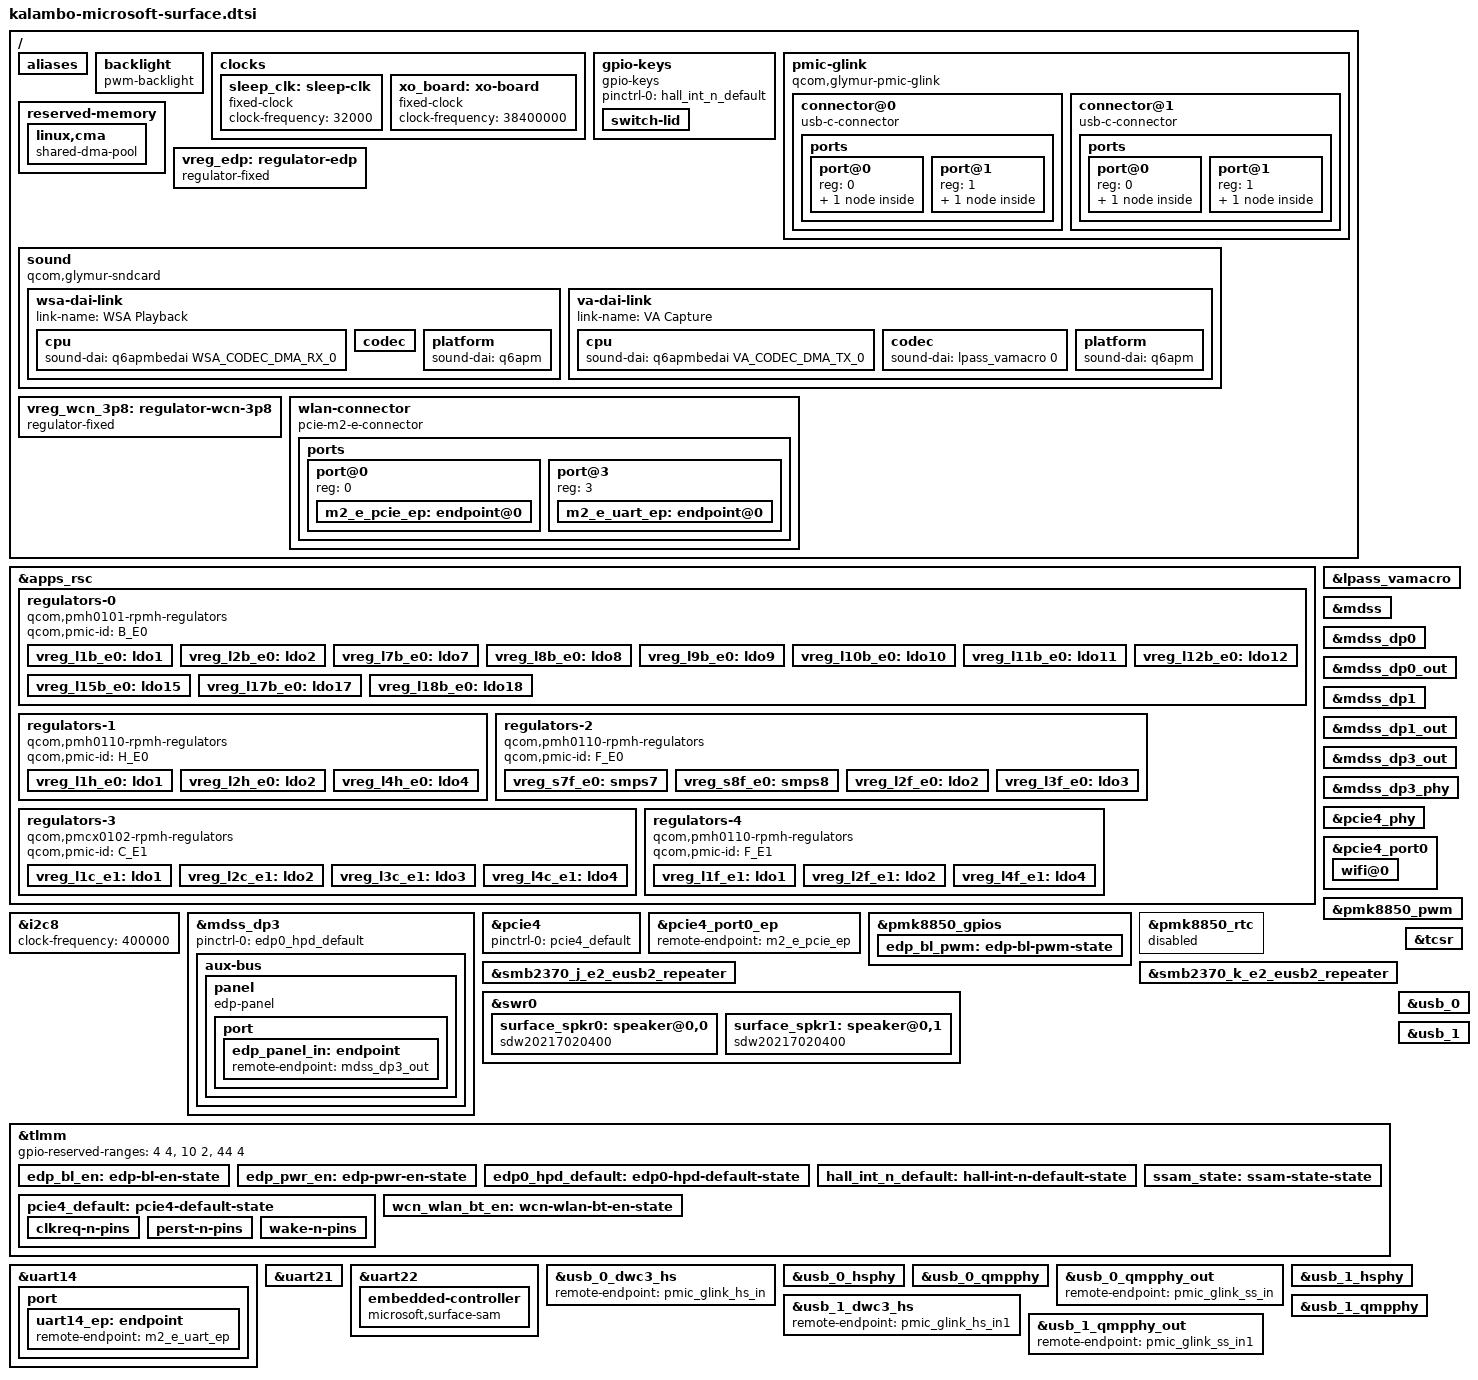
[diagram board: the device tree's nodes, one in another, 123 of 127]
// SPDX-License-Identifier: BSD-3-Clause
/*
 * Parts shared by the Microsoft Surface devices with the 6-core Snapdragon
 * X2 Plus X2P-42-100 (Kalambo): Surface Laptop 13-inch (2nd Edition) and
 * Surface Pro 12-inch (2nd Edition).
 *
 * The PEP power tables of both devices' ACPI tables are the Surface Laptop
 * 8's (Mahua) rail for rail, and their SoC side devices (Surface Serial Hub
 * on UR23, Bluetooth on UR15, Wi-Fi on PCI4, the eDP pins, the speaker
 * amplifier pins) sit where the Surface Laptop 8's do. The SoC wiring is
 * therefore the one glymur-microsoft-surface-laptop8.dts describes, without
 * its USB4 routers: both devices' ACPI tables disable the USB4 router
 * device (UBF0).
 *
 * Copyright (c) Qualcomm Technologies, Inc. and/or its subsidiaries.
 */

#include "pmcx0102.dtsi"
#include "pmh0101.dtsi"
#include "pmh0110-glymur.dtsi"
#include "pmk8850.dtsi"
#include "smb2370.dtsi"

#include <dt-bindings/input/gpio-keys.h>
#include <dt-bindings/input/input.h>

/* As mahua-crd.dts: one pmcx0102 die on SPMI0. */
/delete-node/ &pmcx0102_d_e0;
/delete-node/ &pmcx0102_d0_thermal;

/ {
	aliases {
		i2c8 = &i2c8;

		serial0 = &uart21;
		serial1 = &uart14;
	};

	backlight: backlight {
		compatible = "pwm-backlight";
		pwms = <&pmk8850_pwm 0 5118750>;

		pinctrl-0 = <&edp_bl_pwm>;
		pinctrl-names = "default";
	};

	clocks {
		sleep_clk: sleep-clk {
			compatible = "fixed-clock";
			clock-frequency = <32000>;
			#clock-cells = <0>;
		};

		xo_board: xo-board {
			compatible = "fixed-clock";
			clock-frequency = <38400000>;
			#clock-cells = <0>;
		};
	};

	/*
	 * ACPI \_SB.GIO0.LIDR reads TLMM 2 and \_SB.LIGE takes its wake
	 * interrupt from it on both edges. On the tablet it is the type
	 * cover's Hall sensor.
	 */
	gpio-keys {
		compatible = "gpio-keys";

		pinctrl-0 = <&hall_int_n_default>;
		pinctrl-names = "default";

		switch-lid {
			label = "lid";
			gpios = <&tlmm 2 GPIO_ACTIVE_LOW>;
			linux,input-type = <EV_SW>;
			linux,code = <SW_LID>;
			wakeup-source;
		};
	};

	pmic-glink {
		compatible = "qcom,glymur-pmic-glink",
			     "qcom,pmic-glink";
		#address-cells = <1>;
		#size-cells = <0>;

		connector@0 {
			compatible = "usb-c-connector";
			reg = <0>;
			power-role = "dual";
			data-role = "dual";

			ports {
				#address-cells = <1>;
				#size-cells = <0>;

				port@0 {
					reg = <0>;

					pmic_glink_hs_in: endpoint {
						remote-endpoint = <&usb_0_dwc3_hs>;
					};
				};

				port@1 {
					reg = <1>;

					pmic_glink_ss_in: endpoint {
						remote-endpoint = <&usb_0_qmpphy_out>;
					};
				};
			};
		};

		connector@1 {
			compatible = "usb-c-connector";
			reg = <1>;
			power-role = "dual";
			data-role = "dual";

			ports {
				#address-cells = <1>;
				#size-cells = <0>;

				port@0 {
					reg = <0>;

					pmic_glink_hs_in1: endpoint {
						remote-endpoint = <&usb_1_dwc3_hs>;
					};
				};

				port@1 {
					reg = <1>;

					pmic_glink_ss_in1: endpoint {
						remote-endpoint = <&usb_1_qmpphy_out>;
					};
				};
			};
		};
	};

	reserved-memory {
		linux,cma {
			compatible = "shared-dma-pool";
			size = <0x0 0x10000000>;
			reusable;
			linux,cma-default;
		};
	};

	/* ACPI GPU0 power table: TLMM 70 on for the panel */
	vreg_edp: regulator-edp {
		compatible = "regulator-fixed";

		regulator-name = "VREG_EDP_3P3";
		regulator-min-microvolt = <3300000>;
		regulator-max-microvolt = <3300000>;

		gpio = <&tlmm 70 GPIO_ACTIVE_HIGH>;
		enable-active-high;

		vin-supply = <&vreg_l8b_e0>;

		pinctrl-0 = <&edp_pwr_en>;
		pinctrl-names = "default";

		regulator-boot-on;
	};

	/*
	 * The two WSA8845 amplifiers and two DMICs of the Surface Laptop 8,
	 * whose topology this names: the ACPI audio pins (AUCD, TLMM 204 and
	 * 205) are the Surface Laptop 8's.
	 */
	sound {
		compatible = "qcom,glymur-sndcard";
		model = "GLYMUR-Microsoft-Surface-Laptop-8";
		audio-routing = "SpkrLeft IN", "WSA WSA_SPK1 OUT",
				"SpkrRight IN", "WSA WSA_SPK2 OUT",
				"VA DMIC0", "vdd-micb",
				"VA DMIC1", "vdd-micb";

		wsa-dai-link {
			link-name = "WSA Playback";

			cpu {
				sound-dai = <&q6apmbedai WSA_CODEC_DMA_RX_0>;
			};

			codec {
				sound-dai = <&surface_spkr0>, <&surface_spkr1>,
					    <&swr0 0>, <&lpass_wsamacro 0>;
			};

			platform {
				sound-dai = <&q6apm>;
			};
		};

		va-dai-link {
			link-name = "VA Capture";

			cpu {
				sound-dai = <&q6apmbedai VA_CODEC_DMA_TX_0>;
			};

			codec {
				sound-dai = <&lpass_vamacro 0>;
			};

			platform {
				sound-dai = <&q6apm>;
			};
		};
	};

	/*
	 * ACPI QPPX drives TLMM 117 (Wi-Fi enable) and BTH0 TLMM 116
	 * (Bluetooth enable), the Surface Laptop 8's pins.
	 */
	/*
	 * The Wi-Fi module's main supply. The tables name its INA4230 channel
	 * (WIFI_3P8V) but switch it with no GPIO, so it is always on.
	 */
	vreg_wcn_3p8: regulator-wcn-3p8 {
		compatible = "regulator-fixed";

		regulator-name = "VREG_WCN_3P8";
		regulator-min-microvolt = <3800000>;
		regulator-max-microvolt = <3800000>;

		regulator-always-on;
	};

	wlan-connector {
		compatible = "pcie-m2-e-connector";
		vpcie3v3-supply = <&vreg_wcn_3p8>;
		vpcie1v8-supply = <&vreg_l15b_e0>;

		w-disable1-gpios = <&tlmm 117 GPIO_ACTIVE_LOW>;
		w-disable2-gpios = <&tlmm 116 GPIO_ACTIVE_LOW>;

		pinctrl-0 = <&wcn_wlan_bt_en>;
		pinctrl-names = "default";

		ports {
			#address-cells = <1>;
			#size-cells = <0>;

			port@0 {
				reg = <0>;
				#address-cells = <1>;
				#size-cells = <0>;

				m2_e_pcie_ep: endpoint@0 {
					reg = <0>;
					remote-endpoint = <&pcie4_port0_ep>;
				};
			};

			port@3 {
				reg = <3>;
				#address-cells = <1>;
				#size-cells = <0>;

				m2_e_uart_ep: endpoint@0 {
					reg = <0>;
					remote-endpoint = <&uart14_ep>;
				};
			};
		};
	};
};

/* The PEP rails are the Surface Laptop 8's, and so are these regulators. */
&apps_rsc {
	/* PMH0101 */
	regulators-0 {
		compatible = "qcom,pmh0101-rpmh-regulators";
		qcom,pmic-id = "B_E0";

		vreg_l1b_e0: ldo1 {
			regulator-name = "vreg_l1b_e0";
			regulator-min-microvolt = <1800000>;
			regulator-max-microvolt = <1800000>;
			regulator-initial-mode = <RPMH_REGULATOR_MODE_HPM>;
		};

		/* Unused */
		vreg_l2b_e0: ldo2 {
			regulator-name = "vreg_l2b_e0";
			regulator-min-microvolt = <1800000>;
			regulator-max-microvolt = <1800000>;
		};

		vreg_l7b_e0: ldo7 {
			regulator-name = "vreg_l7b_e0";
			regulator-min-microvolt = <3072000>;
			regulator-max-microvolt = <3072000>;
			regulator-initial-mode = <RPMH_REGULATOR_MODE_HPM>;
		};

		vreg_l8b_e0: ldo8 {
			regulator-name = "vreg_l8b_e0";
			regulator-min-microvolt = <3072000>;
			regulator-max-microvolt = <3304000>;
			regulator-initial-mode = <RPMH_REGULATOR_MODE_HPM>;
		};

		/* Unused */
		vreg_l9b_e0: ldo9 {
			regulator-name = "vreg_l9b_e0";
			regulator-min-microvolt = <2960000>;
			regulator-max-microvolt = <2960000>;
		};

		vreg_l10b_e0: ldo10 {
			regulator-name = "vreg_l10b_e0";
			regulator-min-microvolt = <1800000>;
			regulator-max-microvolt = <1800000>;
			regulator-initial-mode = <RPMH_REGULATOR_MODE_HPM>;
		};

		vreg_l11b_e0: ldo11 {
			regulator-name = "vreg_l11b_e0";
			regulator-min-microvolt = <1200000>;
			regulator-max-microvolt = <1200000>;
			regulator-initial-mode = <RPMH_REGULATOR_MODE_HPM>;
		};

		/* Unused */
		vreg_l12b_e0: ldo12 {
			regulator-name = "vreg_l12b_e0";
			regulator-min-microvolt = <1200000>;
			regulator-max-microvolt = <1200000>;
		};

		vreg_l15b_e0: ldo15 {
			regulator-name = "vreg_l15b_e0";
			regulator-min-microvolt = <1800000>;
			regulator-max-microvolt = <1800000>;
			regulator-initial-mode = <RPMH_REGULATOR_MODE_HPM>;
			/* Provides reference voltage for many undescribed components */
			regulator-always-on;
		};

		/* Unused */
		vreg_l17b_e0: ldo17 {
			regulator-name = "vreg_l17b_e0";
			regulator-min-microvolt = <2504000>;
			regulator-max-microvolt = <2504000>;
		};

		vreg_l18b_e0: ldo18 {
			regulator-name = "vreg_l18b_e0";
			regulator-min-microvolt = <1200000>;
			regulator-max-microvolt = <1200000>;
			regulator-initial-mode = <RPMH_REGULATOR_MODE_HPM>;

			/* Provides reference voltage for many undescribed components */
			regulator-always-on;
		};
	};

	/* PMH0110 H_E0: USB PHY, PCIe 5 PHY and reference rails (firmware power tables) */
	regulators-1 {
		compatible = "qcom,pmh0110-rpmh-regulators";
		qcom,pmic-id = "H_E0";

		vreg_l1h_e0: ldo1 {
			regulator-name = "vreg_l1h_e0";
			regulator-min-microvolt = <936000>;
			regulator-max-microvolt = <936000>;
			regulator-initial-mode = <RPMH_REGULATOR_MODE_HPM>;
		};

		vreg_l2h_e0: ldo2 {
			regulator-name = "vreg_l2h_e0";
			regulator-min-microvolt = <880000>;
			regulator-max-microvolt = <880000>;
			regulator-initial-mode = <RPMH_REGULATOR_MODE_HPM>;
		};

		vreg_l4h_e0: ldo4 {
			regulator-name = "vreg_l4h_e0";
			regulator-min-microvolt = <1200000>;
			regulator-max-microvolt = <1200000>;
			regulator-initial-mode = <RPMH_REGULATOR_MODE_HPM>;
		};
	};

	/* PMH0110 */
	regulators-2 {
		compatible = "qcom,pmh0110-rpmh-regulators";
		qcom,pmic-id = "F_E0";

		vreg_s7f_e0: smps7 {
			regulator-name = "vreg_s7f_e0";
			regulator-min-microvolt = <1200000>;
			regulator-max-microvolt = <1200000>;
			regulator-initial-mode = <RPMH_REGULATOR_MODE_HPM>;
		};

		vreg_s8f_e0: smps8 {
			regulator-name = "vreg_s8f_e0";
			regulator-min-microvolt = <952000>;
			regulator-max-microvolt = <952000>;
			regulator-initial-mode = <RPMH_REGULATOR_MODE_HPM>;
		};

		vreg_l2f_e0: ldo2 {
			regulator-name = "vreg_l2f_e0";
			regulator-min-microvolt = <936000>;
			regulator-max-microvolt = <936000>;
			regulator-initial-mode = <RPMH_REGULATOR_MODE_HPM>;
		};

		vreg_l3f_e0: ldo3 {
			regulator-name = "vreg_l3f_e0";
			regulator-min-microvolt = <912000>;
			regulator-max-microvolt = <912000>;
			regulator-initial-mode = <RPMH_REGULATOR_MODE_HPM>;
		};
	};

	regulators-3 {
		compatible = "qcom,pmcx0102-rpmh-regulators";
		qcom,pmic-id = "C_E1";

		vreg_l1c_e1: ldo1 {
			regulator-name = "vreg_l1c_e1";
			regulator-min-microvolt = <912000>;
			regulator-max-microvolt = <912000>;
			regulator-initial-mode = <RPMH_REGULATOR_MODE_HPM>;
		};

		vreg_l2c_e1: ldo2 {
			regulator-name = "vreg_l2c_e1";
			regulator-min-microvolt = <1200000>;
			regulator-max-microvolt = <1200000>;
			regulator-initial-mode = <RPMH_REGULATOR_MODE_HPM>;
		};

		vreg_l3c_e1: ldo3 {
			regulator-name = "vreg_l3c_e1";
			regulator-min-microvolt = <936000>;
			regulator-max-microvolt = <936000>;
			regulator-initial-mode = <RPMH_REGULATOR_MODE_HPM>;
		};

		vreg_l4c_e1: ldo4 {
			regulator-name = "vreg_l4c_e1";
			regulator-min-microvolt = <912000>;
			regulator-max-microvolt = <912000>;
			regulator-initial-mode = <RPMH_REGULATOR_MODE_HPM>;
		};
	};

	/* PMH0110 */
	regulators-4 {
		compatible = "qcom,pmh0110-rpmh-regulators";
		qcom,pmic-id = "F_E1";

		vreg_l1f_e1: ldo1 {
			regulator-name = "vreg_l1f_e1";
			regulator-min-microvolt = <904000>;
			regulator-max-microvolt = <904000>;
			regulator-initial-mode = <RPMH_REGULATOR_MODE_HPM>;
		};

		vreg_l2f_e1: ldo2 {
			regulator-name = "vreg_l2f_e1";
			regulator-min-microvolt = <880000>;
			regulator-max-microvolt = <880000>;
			regulator-initial-mode = <RPMH_REGULATOR_MODE_HPM>;
		};

		vreg_l4f_e1: ldo4 {
			regulator-name = "vreg_l4f_e1";
			regulator-min-microvolt = <1200000>;
			regulator-max-microvolt = <1200000>;
			regulator-initial-mode = <RPMH_REGULATOR_MODE_HPM>;
		};
	};
};

&i2c8 {
	clock-frequency = <400000>;

	status = "okay";
};

&lpass_vamacro {
	vdd-micb-supply = <&vreg_l1b_e0>;

	pinctrl-0 = <&dmic01_default>;
	pinctrl-names = "default";

	qcom,dmic-sample-rate = <2400000>;
};

&mdss {
	status = "okay";
};

/* DisplayPort alternate mode on the two USB-C ports */
&mdss_dp0 {
	status = "okay";
};

&mdss_dp0_out {
	link-frequencies = /bits/ 64 <1620000000 2700000000 5400000000 8100000000>;
};

&mdss_dp1 {
	status = "okay";
};

&mdss_dp1_out {
	link-frequencies = /bits/ 64 <1620000000 2700000000 5400000000 8100000000>;
};

&mdss_dp3 {
	/delete-property/ #sound-dai-cells;

	pinctrl-0 = <&edp0_hpd_default>;
	pinctrl-names = "default";

	status = "okay";

	aux-bus {
		panel {
			/*
			 * ACPI GPU0 power table: TLMM 70 (power), TLMM 18
			 * (enable) and TLMM 119 (hot plug), and PMK8850 GPIO 5
			 * as the backlight PWM output.
			 */
			compatible = "edp-panel";
			backlight = <&backlight>;
			enable-gpios = <&tlmm 18 GPIO_ACTIVE_HIGH>;
			power-supply = <&vreg_edp>;

			pinctrl-0 = <&edp_bl_en>;
			pinctrl-names = "default";

			port {
				edp_panel_in: endpoint {
					remote-endpoint = <&mdss_dp3_out>;
				};
			};
		};
	};
};

&mdss_dp3_out {
	/* The rates the Surface Laptop 8's eDP link has run at */
	data-lanes = <0 1 2 3>;
	link-frequencies = /bits/ 64 <1620000000 2700000000 5400000000>;

	remote-endpoint = <&edp_panel_in>;
};

&mdss_dp3_phy {
	vdda-phy-supply = <&vreg_l2f_e1>;
	vdda-pll-supply = <&vreg_l4f_e1>;

	status = "okay";
};

&pcie4 {
	pinctrl-0 = <&pcie4_default>;
	pinctrl-names = "default";

	status = "okay";
};

&pcie4_phy {
	vdda-phy-supply = <&vreg_l1c_e1>;
	vdda-pll-supply = <&vreg_l4f_e1>;

	status = "okay";
};

/* ACPI PCI4: reset TLMM 146, wake TLMM 148 (virtual pin 0x180) */
&pcie4_port0 {
	reset-gpios = <&tlmm 146 GPIO_ACTIVE_LOW>;
	wake-gpios = <&tlmm 148 GPIO_ACTIVE_LOW>;

	/*
	 * The Surface Laptop 8's WCN7850 reads its rfkill input as "radio off".
	 * ACPI BTH0 is the Surface Laptop 8's here, but the chip is not named,
	 * so the node has no compatible.
	 */
	wifi@0 {
		reg = <0x10000 0x0 0x0 0x0 0x0>;

		disable-rfkill;
	};
};

&pcie4_port0_ep {
	remote-endpoint = <&m2_e_pcie_ep>;
};

&pmk8850_gpios {
	edp_bl_pwm: edp-bl-pwm-state {
		pins = "gpio5";
		function = "func3";
	};
};

&pmk8850_pwm {
	status = "okay";
};

&pmk8850_rtc {
	/* The time is kept by the Surface Serial Hub (rtc-surface). */
	status = "disabled";
};

&smb2370_j_e2_eusb2_repeater {
	vdd18-supply = <&vreg_l15b_e0>;
	vdd3-supply = <&vreg_l7b_e0>;
};

&smb2370_k_e2_eusb2_repeater {
	vdd18-supply = <&vreg_l15b_e0>;
	vdd3-supply = <&vreg_l7b_e0>;
};

&swr0 {
	status = "okay";

	surface_spkr0: speaker@0,0 {
		compatible = "sdw20217020400";
		reg = <0 0>;
		reset-gpios = <&tlmm 204 GPIO_ACTIVE_LOW>;
		#sound-dai-cells = <0>;
		sound-name-prefix = "SpkrLeft";
		vdd-1p8-supply = <&vreg_l15b_e0>;
		vdd-io-supply = <&vreg_l18b_e0>;
		qcom,port-mapping = <1 2 3 7 12 14>;
	};

	surface_spkr1: speaker@0,1 {
		compatible = "sdw20217020400";
		reg = <0 1>;
		reset-gpios = <&tlmm 204 GPIO_ACTIVE_LOW>;
		#sound-dai-cells = <0>;
		sound-name-prefix = "SpkrRight";
		vdd-1p8-supply = <&vreg_l15b_e0>;
		vdd-io-supply = <&vreg_l18b_e0>;
		qcom,port-mapping = <4 5 6 7 13 15>;
	};
};

&tcsr {
	vdda-qrefrpt0-0p9-supply = <&vreg_l2f_e1>;
	vdda-qrefrpt1-0p9-supply = <&vreg_l2f_e1>;
	vdda-qrefrpt2-0p9-supply = <&vreg_l2f_e1>;
	vdda-qrefrpt3-0p9-supply = <&vreg_l1f_e1>;
	vdda-qrefrpt4-0p9-supply = <&vreg_l2h_e0>;
	vdda-qrefrpt5-0p9-supply = <&vreg_l2h_e0>;
	vdda-qrefrx0-0p9-supply = <&vreg_l2f_e1>;
	vdda-qrefrx1-0p9-supply = <&vreg_l2f_e1>;
	vdda-qrefrx2-0p9-supply = <&vreg_l2f_e1>;
	vdda-qrefrx3-0p9-supply = <&vreg_l2h_e0>;
	vdda-qreftx1-0p9-supply = <&vreg_l1f_e1>;
	vdda-refgen3-0p9-supply = <&vreg_l1f_e1>;
	vdda-refgen3-1p2-supply = <&vreg_l4f_e1>;
};

&tlmm {
	gpio-reserved-ranges = <4 4>, /* EC Secure I3C */
			       <10 2>, /* OOB UART */
			       <44 4>; /* TPM */

	edp_bl_en: edp-bl-en-state {
		pins = "gpio18";
		function = "gpio";
		drive-strength = <16>;
		bias-disable;
	};

	edp_pwr_en: edp-pwr-en-state {
		pins = "gpio70";
		function = "gpio";
		drive-strength = <16>;
		bias-disable;
	};

	edp0_hpd_default: edp0-hpd-default-state {
		pins = "gpio119";
		function = "edp0_hot";
		bias-disable;
	};

	hall_int_n_default: hall-int-n-default-state {
		pins = "gpio2";
		function = "gpio";
		bias-disable;
	};

	pcie4_default: pcie4-default-state {
		clkreq-n-pins {
			pins = "gpio147";
			function = "pcie4_clk_req_n";
			drive-strength = <2>;
			bias-pull-up;
		};

		perst-n-pins {
			pins = "gpio146";
			function = "gpio";
			drive-strength = <2>;
			bias-disable;
		};

		wake-n-pins {
			pins = "gpio148";
			function = "gpio";
			drive-strength = <2>;
			bias-pull-up;
		};
	};

	ssam_state: ssam-state-state {
		pins = "gpio71";
		function = "gpio";
		bias-disable;
	};

	wcn_wlan_bt_en: wcn-wlan-bt-en-state {
		pins = "gpio116", "gpio117";
		function = "gpio";
		drive-strength = <2>;
		bias-disable;
	};
};

/* ACPI UR15 @ 0xa98000: Bluetooth (BTH0) */
&uart14 {
	status = "okay";

	port {
		uart14_ep: endpoint {
			remote-endpoint = <&m2_e_uart_ep>;
		};
	};
};

/* ACPI UARD @ 0x894000, the SPCR and DBG2 console at 115200 baud */
&uart21 {
	status = "okay";
};

/*
 * ACPI UR23 @ 0x898000: Surface Serial Hub, MSHW0084, at 4 Mbaud (SUBR
 * 0x3d0900). Its wake interrupt, GIO0 virtual pin 0x300, is TLMM 71: the
 * ninth interrupt after the four summary interrupts of GIO0._CRS, GSIV
 * 0x2f2, is SPI 722, which kalambo.dtsi's PDC ranges make PDC pin 135, and
 * the Mahua PDC map makes that TLMM 71.
 */
&uart22 {
	status = "okay";

	embedded-controller {
		compatible = "microsoft,surface-sam";

		interrupts-extended = <&tlmm 71 IRQ_TYPE_EDGE_RISING>;

		current-speed = <4000000>;

		pinctrl-0 = <&ssam_state>;
		pinctrl-names = "default";
	};
};

/* ACPI URS0 and URS1: the two USB-C ports; URS2 is disabled. */
&usb_0 {
	status = "okay";
};

&usb_0_dwc3_hs {
	remote-endpoint = <&pmic_glink_hs_in>;
};

&usb_0_hsphy {
	vdd-supply = <&vreg_l3f_e0>;
	vdda12-supply = <&vreg_l4h_e0>;

	phys = <&smb2370_j_e2_eusb2_repeater>;

	status = "okay";
};

&usb_0_qmpphy {
	vdda-phy-supply = <&vreg_l3f_e0>;
	vdda-pll-supply = <&vreg_l4h_e0>;
	refgen-supply = <&vreg_l2f_e0>;

	status = "okay";
};

&usb_0_qmpphy_out {
	remote-endpoint = <&pmic_glink_ss_in>;
};

&usb_1 {
	status = "okay";
};

&usb_1_dwc3_hs {
	remote-endpoint = <&pmic_glink_hs_in1>;
};

&usb_1_hsphy {
	vdd-supply = <&vreg_l3f_e0>;
	vdda12-supply = <&vreg_l4h_e0>;

	phys = <&smb2370_k_e2_eusb2_repeater>;

	status = "okay";
};

&usb_1_qmpphy {
	vdda-phy-supply = <&vreg_l1h_e0>;
	vdda-pll-supply = <&vreg_l4h_e0>;
	refgen-supply = <&vreg_l2f_e0>;

	status = "okay";
};

&usb_1_qmpphy_out {
	remote-endpoint = <&pmic_glink_ss_in1>;
};
